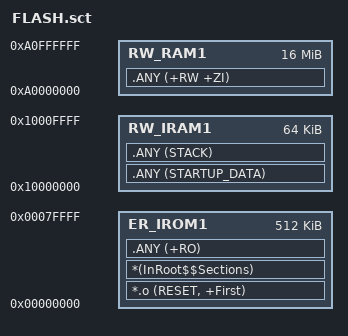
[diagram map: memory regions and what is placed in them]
; *************************************************************
; *** Scatter-Loading Description File generated by uVision ***
; *************************************************************

LR_IROM1 0x00000000 0x00080000  {    ; load region size_region
  ER_IROM1 0x00000000 0x00080000  {  ; load address = execution address
   *.o (RESET, +First)
   *(InRoot$$Sections)
   .ANY (+RO)
  }
  RW_IRAM1 0x10000000 0x00010000  {
   .ANY (STARTUP_DATA)
   .ANY (STACK)
  }
  RW_RAM1 0xA0000000 0x01000000  {
   .ANY (+RW +ZI)  
  }
}

;LR_IROM2 0x90000000 0x00200000  {    ; load region size_region
;  ER_IROM2 0x90000000 0x00200000  {  ; load address = execution address
;   *.lib (+RO)
;  }
;}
